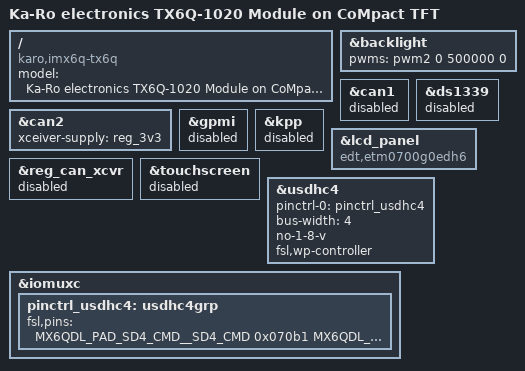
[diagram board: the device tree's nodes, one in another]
/*
 * Copyright 2014-2017 Lothar Waßmann <LW@KARO-electronics.de>
 *
 * This file is dual-licensed: you can use it either under the terms
 * of the GPL or the X11 license, at your option. Note that this dual
 * licensing only applies to this file, and not this project as a
 * whole.
 *
 *  a) This file is free software; you can redistribute it and/or
 *     modify it under the terms of the GNU General Public License
 *     version 2 as published by the Free Software Foundation.
 *
 *     This file is distributed in the hope that it will be useful,
 *     but WITHOUT ANY WARRANTY; without even the implied warranty of
 *     MERCHANTABILITY or FITNESS FOR A PARTICULAR PURPOSE.  See the
 *     GNU General Public License for more details.
 *
 * Or, alternatively,
 *
 *  b) Permission is hereby granted, free of charge, to any person
 *     obtaining a copy of this software and associated documentation
 *     files (the "Software"), to deal in the Software without
 *     restriction, including without limitation the rights to use,
 *     copy, modify, merge, publish, distribute, sublicense, and/or
 *     sell copies of the Software, and to permit persons to whom the
 *     Software is furnished to do so, subject to the following
 *     conditions:
 *
 *     The above copyright notice and this permission notice shall be
 *     included in all copies or substantial portions of the Software.
 *
 *     THE SOFTWARE IS PROVIDED "AS IS", WITHOUT WARRANTY OF ANY KIND,
 *     EXPRESS OR IMPLIED, INCLUDING BUT NOT LIMITED TO THE WARRANTIES
 *     OF MERCHANTABILITY, FITNESS FOR A PARTICULAR PURPOSE AND
 *     NONINFRINGEMENT. IN NO EVENT SHALL THE AUTHORS OR COPYRIGHT
 *     HOLDERS BE LIABLE FOR ANY CLAIM, DAMAGES OR OTHER LIABILITY,
 *     WHETHER IN AN ACTION OF CONTRACT, TORT OR OTHERWISE, ARISING
 *     FROM, OUT OF OR IN CONNECTION WITH THE SOFTWARE OR THE USE OR
 *     OTHER DEALINGS IN THE SOFTWARE.
 */

/dts-v1/;
#include "imx6q.dtsi"
#include "imx6qdl-tx6.dtsi"
#include "imx6qdl-tx6-lcd.dtsi"

/ {
	model = "Ka-Ro electronics TX6Q-1020 Module on CoMpact TFT";
	compatible = "karo,imx6q-tx6q", "fsl,imx6q";
};

&backlight {
	pwms = <&pwm2 0 500000 0>;
};

&can1 {
	status = "disabled";
};

&can2 {
	xceiver-supply = <&reg_3v3>;
};

&ds1339 {
	status = "disabled";
};

&gpmi {
	status = "disabled";
};

&kpp {
	status = "disabled";
};

&lcd_panel {
	compatible = "edt,etm0700g0edh6";
};

&reg_can_xcvr {
	status = "disabled";
};

&touchscreen {
	status = "disabled";
};

&usdhc4 {
	pinctrl-names = "default";
	pinctrl-0 = <&pinctrl_usdhc4>;
	bus-width = <4>;
	no-1-8-v;
	fsl,wp-controller;
	status = "okay";
};

&iomuxc {
	pinctrl_usdhc4: usdhc4grp {
		fsl,pins = <
			MX6QDL_PAD_SD4_CMD__SD4_CMD		0x070b1
			MX6QDL_PAD_SD4_CLK__SD4_CLK		0x070b1
			MX6QDL_PAD_SD4_DAT0__SD4_DATA0		0x070b1
			MX6QDL_PAD_SD4_DAT1__SD4_DATA1		0x070b1
			MX6QDL_PAD_SD4_DAT2__SD4_DATA2		0x070b1
			MX6QDL_PAD_SD4_DAT3__SD4_DATA3		0x070b1
			MX6QDL_PAD_NANDF_ALE__SD4_RESET		0x0b0b1
		>;
	};
};
